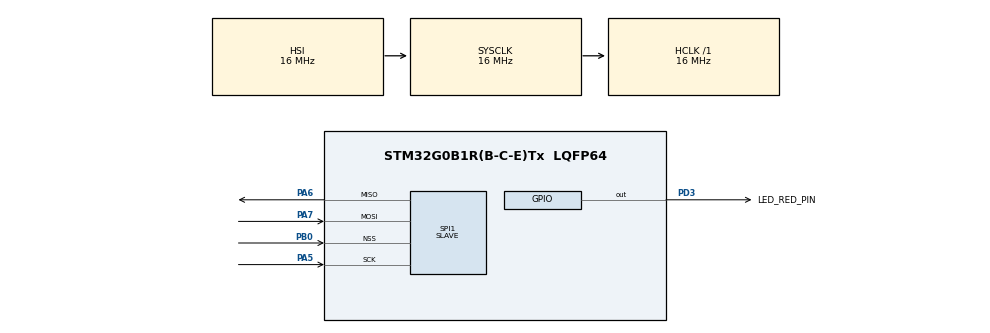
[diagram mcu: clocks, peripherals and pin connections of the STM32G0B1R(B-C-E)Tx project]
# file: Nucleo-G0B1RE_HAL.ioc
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Mcu.Family=STM32G0
Mcu.Name=STM32G0B1R(B-C-E)Tx
Mcu.Package=LQFP64
PA5.Mode=Full_Duplex_Slave
PA5.Signal=SPI1_SCK
PA6.Mode=Full_Duplex_Slave
PA6.Signal=SPI1_MISO
PA7.Mode=Full_Duplex_Slave
PA7.Signal=SPI1_MOSI
PB0.Mode=NSS_Signal_Hard_Input
PB0.Signal=SPI1_NSS
PD3.GPIO_Label=LED_RED_PIN
PD3.GPIO_Speed=GPIO_SPEED_FREQ_VERY_HIGH
PD3.PinState=GPIO_PIN_SET
PD3.Signal=GPIO_Output
ProjectManager.HeapSize=0x200
ProjectManager.StackSize=0x400
ProjectManager.TargetToolchain=STM32CubeIDE
RCC.AHBFreq_Value=16000000
RCC.CortexFreq_Value=16000000
RCC.EXTERNAL_CLOCK_VALUE=12288000
RCC.HCLKFreq_Value=16000000
RCC.HSE_VALUE=8000000
RCC.HSI48_VALUE=48000000
RCC.HSI_VALUE=16000000
RCC.LSE_VALUE=32768
RCC.SYSCLKFreq_VALUE=16000000
RCC.USBFreq_Value=48000000
RCC.VCOOutputFreq_Value=128000000
SPI1.CLKPhase=SPI_PHASE_2EDGE
SPI1.CLKPolarity=SPI_POLARITY_HIGH
SPI1.Direction=SPI_DIRECTION_2LINES
SPI1.Mode=SPI_MODE_SLAVE
SPI1.VirtualNSS=VM_NSSHARD
SPI1.VirtualType=VM_SLAVE
VP_SYS_VS_DBSignals.Mode=DisableDeadBatterySignals
board=NUCLEO-G0B1RE

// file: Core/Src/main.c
/* USER CODE BEGIN Header */
/**
  ******************************************************************************
  * @file           : main.c
  * @brief          : Main program body
  ******************************************************************************
  * @attention
  *
  * Copyright (c) 2024 STMicroelectronics.
  * All rights reserved.
  *
  * This software is licensed under terms that can be found in the LICENSE file
  * in the root directory of this software component.
  * If no LICENSE file comes with this software, it is provided AS-IS.
  *
  ******************************************************************************
  */
/* USER CODE END Header */
#include "main.h"

SPI_HandleTypeDef hspi1;

void SystemClock_Config(void);
static void MX_GPIO_Init(void);
static void MX_SPI1_Init(void);

int main(void)
{
  /* USER CODE BEGIN 1 */
	uint8_t ack_byte = 0xF5;
	uint8_t dataLoaded = 0;
	uint8_t dummy_byte = 0x0;
  /* USER CODE END 1 */

  /* MCU Configuration--------------------------------------------------------*/

  /* Reset of all peripherals, Initializes the Flash interface and the Systick. */
  HAL_Init();

  /* Configure the system clock */
  SystemClock_Config();

  /* Initialize all configured peripherals */
  MX_GPIO_Init();
  MX_SPI1_Init();

  /* Infinite loop */
  while (1)
  {
	 //HAL_SPI_Transmit(&hspi1, &dummy_byte, 1, 1);
	 HAL_SPI_Receive(&hspi1, &dataLoaded, 1, 100);

	 if(ack_byte == 0x50)
	 {
		 HAL_SPI_Transmit(&hspi1, &ack_byte, 1, 100);

	 }
  }
}

void SystemClock_Config(void)
{
  RCC_OscInitTypeDef RCC_OscInitStruct = {0};
  RCC_ClkInitTypeDef RCC_ClkInitStruct = {0};

  /** Configure the main internal regulator output voltage
  */
  HAL_PWREx_ControlVoltageScaling(PWR_REGULATOR_VOLTAGE_SCALE1);

  /** Initializes the RCC Oscillators according to the specified parameters
  * in the RCC_OscInitTypeDef structure.
  */
  RCC_OscInitStruct.OscillatorType = RCC_OSCILLATORTYPE_HSI;
  RCC_OscInitStruct.HSIState = RCC_HSI_ON;
  RCC_OscInitStruct.HSIDiv = RCC_HSI_DIV1;
  RCC_OscInitStruct.HSICalibrationValue = RCC_HSICALIBRATION_DEFAULT;
  RCC_OscInitStruct.PLL.PLLState = RCC_PLL_NONE;
  if (HAL_RCC_OscConfig(&RCC_OscInitStruct) != HAL_OK)
  {
    Error_Handler();
  }

  /** Initializes the CPU, AHB and APB buses clocks
  */
  RCC_ClkInitStruct.ClockType = RCC_CLOCKTYPE_HCLK|RCC_CLOCKTYPE_SYSCLK
                              |RCC_CLOCKTYPE_PCLK1;
  RCC_ClkInitStruct.SYSCLKSource = RCC_SYSCLKSOURCE_HSI;
  RCC_ClkInitStruct.AHBCLKDivider = RCC_SYSCLK_DIV1;
  RCC_ClkInitStruct.APB1CLKDivider = RCC_HCLK_DIV1;

  if (HAL_RCC_ClockConfig(&RCC_ClkInitStruct, FLASH_LATENCY_0) != HAL_OK)
  {
    Error_Handler();
  }
}

static void MX_SPI1_Init(void)
{

  /* SPI1 parameter configuration*/
  hspi1.Instance = SPI1;
  hspi1.Init.Mode = SPI_MODE_SLAVE;
  hspi1.Init.Direction = SPI_DIRECTION_2LINES;
  hspi1.Init.DataSize = SPI_DATASIZE_8BIT;
  hspi1.Init.CLKPolarity = SPI_POLARITY_HIGH;
  hspi1.Init.CLKPhase = SPI_PHASE_2EDGE;
  hspi1.Init.NSS = SPI_NSS_HARD_INPUT;
  hspi1.Init.FirstBit = SPI_FIRSTBIT_MSB;
  hspi1.Init.TIMode = SPI_TIMODE_DISABLE;
  hspi1.Init.CRCCalculation = SPI_CRCCALCULATION_DISABLE;
  hspi1.Init.CRCPolynomial = 7;
  hspi1.Init.CRCLength = SPI_CRC_LENGTH_DATASIZE;
  hspi1.Init.NSSPMode = SPI_NSS_PULSE_DISABLE;
  if (HAL_SPI_Init(&hspi1) != HAL_OK)
  {
    Error_Handler();
  }

}

static void MX_GPIO_Init(void)
{
  GPIO_InitTypeDef GPIO_InitStruct = {0};

  /* GPIO Ports Clock Enable */
  __HAL_RCC_GPIOA_CLK_ENABLE();
  __HAL_RCC_GPIOB_CLK_ENABLE();
  __HAL_RCC_GPIOD_CLK_ENABLE();

  /*Configure GPIO pin Output Level */
  HAL_GPIO_WritePin(LED_RED_PIN_GPIO_Port, LED_RED_PIN_Pin, GPIO_PIN_SET);

  /*Configure GPIO pin : LED_RED_PIN_Pin */
  GPIO_InitStruct.Pin = LED_RED_PIN_Pin;
  GPIO_InitStruct.Mode = GPIO_MODE_OUTPUT_PP;
  GPIO_InitStruct.Pull = GPIO_NOPULL;
  GPIO_InitStruct.Speed = GPIO_SPEED_FREQ_VERY_HIGH;
  HAL_GPIO_Init(LED_RED_PIN_GPIO_Port, &GPIO_InitStruct);

}

void Error_Handler(void)
{
  __disable_irq();
  while (1)
  {
  }
}
